# LPC11Exx register map
File version: 5
CPU: CM0 r0p0, little endian, no MPU, no FPU, 0x2 interrupt priority bits, 0x0 interrupts
Registers are 32-bit, read-write, reset 0x0 unless marked. A register's access mark holds for its fields unless they carry their own. Offsets are from the block's base; [hi:lo] are bit positions; {n}, {i} and the like mark numbered series.

## SYSCON — System control block
Base 0x40048000
0x00 SYSMEMREMAP — System memory remap
  [1:0] MAP — System memory remap. Value 0x3 is reserved.
    0=BOOT_LOADER_MODE_IN (Boot Loader Mode. Interrupt vectors are re-mapped to Boot ROM.); 1=USER_RAM_MODE_INTER (User RAM Mode. Interrupt vectors are re-mapped to Static RAM.); 2=USER_FLASH_MODE_INT (User Flash Mode. Interrupt vectors are not re-mapped and reside in Flash.)
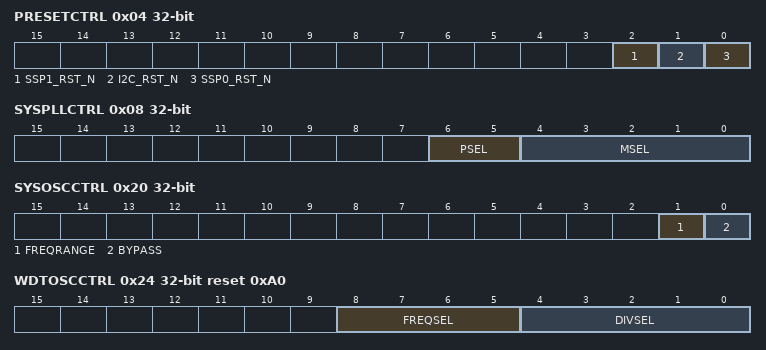
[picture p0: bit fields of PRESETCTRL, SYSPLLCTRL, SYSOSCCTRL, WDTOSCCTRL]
0x04 PRESETCTRL — Peripheral reset control
  [2] SSP1_RST_N — SSP1 reset control
    0=RESETS_THE_SSP1_PERI (Resets the SSP1 peripheral.); 1=SSP1_RESET_DE_ASSERT (SSP1 reset de-asserted.)
  [1] I2C_RST_N — I2C reset control
    0=RESETS_THE_I2C_PERIP (Resets the I2C peripheral.); 1=I2C_RESET_DE_ASSERTE (I2C reset de-asserted.)
  [0] SSP0_RST_N — SSP0 reset control
    0=RESETS_THE_SSP0_PERI (Resets the SSP0 peripheral.); 1=SSP0_RESET_DE_ASSERT (SSP0 reset de-asserted.)
0x08 SYSPLLCTRL — System PLL control
  [6:5] PSEL — Post divider ratio P. The division ratio is 2 x P.
    0=P_EQ_1 (P = 1); 1=P_EQ_2 (P = 2); 2=P_EQ_4 (P = 4); 3=P_EQ_8 (P = 8)
  [4:0] MSEL — Feedback divider value. The division value M is the programmed MSEL value + 1. 00000: Division ratio M = 1 to 11111: Division ratio M = 32
0x0C SYSPLLSTAT ro — System PLL status
  [0] LOCK — PLL lock status
    0=PLL_NOT_LOCKED; 1=PLL_LOCKED
0x20 SYSOSCCTRL — System oscillator control
  [1] FREQRANGE — Determines frequency range for Low-power oscillator.
    0=1__20_MHZ_FREQUENCY (1 - 20 MHz frequency range.); 1=15__25_MHZ_FREQUENC (15 - 25 MHz frequency range)
  [0] BYPASS — Bypass system oscillator
    0=OSCILLATOR_IS_NOT_BY (Oscillator is not bypassed.); 1=BYPASS_ENABLED_PLL_ (Bypass enabled. PLL input (sys_osc_clk) is fed directly from the XTALIN pin bypassing the oscillator. Use this mode when using an external clock source instead of the crystal oscillator.)
0x24 WDTOSCCTRL reset 0xA0 — Watchdog oscillator control
  [8:5] FREQSEL — Select watchdog oscillator analog output frequency (Fclkana).
    1=0_6_MHZ; 2=1_05_MHZ; 3=1_4_MHZ; 4=1_75_MHZ; 5=2_1_MHZ; 6=2_4_MHZ; 7=2_7_MHZ; 8=3_0_MHZ; 9=3_25_MHZ; 10=3_5_MHZ; 11=3_75_MHZ; 12=4_0_MHZ; 13=4_2_MHZ; 14=4_4_MHZ; 15=4_6_MHZ
  [4:0] DIVSEL — Select divider for Fclkana. wdt_osc_clk = Fclkana/ (2 x (1 + DIVSEL)) 00000: 2 x (1 + DIVSEL) = 2 00001: 2 x (1 + DIVSEL) = 4 to 11111: 2 x (1 + DIVSEL) = 64
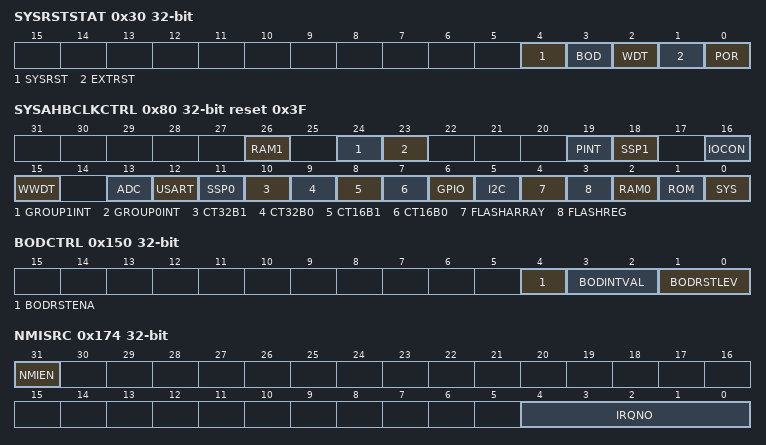
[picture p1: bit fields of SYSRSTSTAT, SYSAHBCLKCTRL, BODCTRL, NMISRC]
0x30 SYSRSTSTAT — System reset status register
  [4] SYSRST — Status of the software system reset
    0=NO_SYSTEM_RESET_DETE (No System reset detected); 1=SYSTEM_RESET_DETECTE (System reset detected. Writing a one clears this reset.)
  [3] BOD — Status of the Brown-out detect reset
    0=NO_BOD_RESET_DETECTE (No BOD reset detected); 1=BOD_RESET_DETECTED_ (BOD reset detected. Writing a one clears this reset.)
  [2] WDT — Status of the Watchdog reset
    0=NO_WDT_RESET_DETECTE (No WDT reset detected); 1=WDT_RESET_DETECTED_ (WDT reset detected. Writing a one clears this reset.)
  [1] EXTRST — External reset status
    0=NO_RESET_EVENT_DETEC (No reset event detected.); 1=RESET_DETECTED_WRIT (Reset detected. Writing a one clears this reset.)
  [0] POR — POR reset status
    0=NO_POR_DETECTED; 1=POR_DETECTED_WRITIN (POR detected. Writing a one clears this reset.)
0x40 SYSPLLCLKSEL — System PLL clock source select
  [1:0] SEL — System PLL clock source
    0=IRC; 1=CRYSTAL_OSCILLATOR_ (Crystal Oscillator (SYSOSC))
0x44 SYSPLLCLKUEN — System PLL clock source update enable
  [0] ENA — Enable system PLL clock source update
    0=NO_CHANGE; 1=UPDATE_CLOCK_SOURCE
0x70 MAINCLKSEL — Main clock source select
  [1:0] SEL — Clock source for main clock
    0=IRC_OSCILLATOR; 1=PLL_INPUT; 2=WATCHDOG_OSCILLATOR; 3=PLL_OUTPUT
0x74 MAINCLKUEN — Main clock source update enable
  [0] ENA — Enable main clock source update
    0=NO_CHANGE; 1=UPDATE_CLOCK_SOURCE
0x78 SYSAHBCLKDIV reset 0x1 — System clock divider
  [7:0] DIV — System AHB clock divider values 0: System clock disabled. 1: Divide by 1. to 255: Divide by 255.
0x80 SYSAHBCLKCTRL reset 0x3F — System clock control
  [26] RAM1 — Enables clock for the SRAM block at address range 0x2000 0000 to 0x2000 0800.
    0=DISABLE; 1=ENABLE
  [24] GROUP1INT — Enables clock to GPIO GROUP1 interrupt register interface.
    0=DISABLE; 1=ENABLE
  [23] GROUP0INT — Enables clock to GPIO GROUP0 interrupt register interface.
    0=DISABLE; 1=ENABLE
  [19] PINT — Enables clock to GPIO Pin interrupts register interface.
    0=DISABLE; 1=ENABLE
  [18] SSP1 — Enables clock for SSP1.
    0=DISABLE; 1=ENABLE
  [16] IOCON — Enables clock for I/O configuration block.
    0=DISABLE; 1=ENABLE
  [15] WWDT — Enables clock for WWDT.
    0=DISABLE; 1=ENABLE
  [13] ADC — Enables clock for ADC.
    0=DISABLE; 1=ENABLE
  [12] USART — Enables clock for UART.
    0=DISABLE; 1=ENABLE
  [11] SSP0 — Enables clock for SSP0.
    0=DISABLE; 1=ENABLE
  [10] CT32B1 — Enables clock for 32-bit counter/timer 1.
    0=DISABLE; 1=ENABLE
  [9] CT32B0 — Enables clock for 32-bit counter/timer 0.
    0=DISABLE; 1=ENABLE
  [8] CT16B1 — Enables clock for 16-bit counter/timer 1.
    0=DISABLE; 1=ENABLE
  [7] CT16B0 — Enables clock for 16-bit counter/timer 0.
    0=DISABLE; 1=ENABLE
  [6] GPIO — Enables clock for GPIO port registers.
    0=DISABLE; 1=ENABLE
  [5] I2C — Enables clock for I2C.
    0=DISABLE; 1=ENABLE
  [4] FLASHARRAY — Enables clock for flash array access.
    0=DISABLE; 1=ENABLE
  [3] FLASHREG — Enables clock for flash register interface.
    0=DISABLE; 1=ENABLE
  [2] RAM0 — Enables clock for the SRAM block at address range 0x1000 0000 to 0x1000 2000.
    0=DISABLE; 1=ENABLE
  [1] ROM — Enables clock for ROM.
    0=DISABLE; 1=ENABLE
  [0] SYS — Enables the clock for the AHB, the APB bridge, the Cortex-M0 FCLK and HCLK, SysCon, and the PMU. This bit is read only and always reads as 1.
    1=ENABLE
0x94 SSP0CLKDIV — SSP0 clock divider
  [7:0] DIV — SPI0_PCLK clock divider values. 0: System clock disabled. 1: Divide by 1. to 255: Divide by 255.
0x98 UARTCLKDIV — UART clock divider
  [7:0] DIV — UART_PCLK clock divider values 0: Disable UART_PCLK. 1: Divide by 1. to 255: Divide by 255.
0x9C SSP1CLKDIV — SSP1 clock divider
  [7:0] DIV — SSP1_PCLK clock divider values 0: Disable SSP1_PCLK. 1: Divide by 1. to 255: Divide by 255.
0xE0 CLKOUTSEL — CLKOUT clock source select
  [1:0] SEL — CLKOUT clock source
    0=IRC_OSCILLATOR; 1=CRYSTAL_OSCILLATOR_ (Crystal oscillator (SYSOSC)); 2=LF_OSCILLATOR; 3=MAIN_CLOCK
0xE4 CLKOUTUEN — CLKOUT clock source update enable
  [0] ENA — Enable CLKOUT clock source update
    0=NO_CHANGE; 1=UPDATE_CLOCK_SOURCE
0xE8 CLKOUTDIV — CLKOUT clock divider
  [7:0] DIV — CLKOUT clock divider values 0: Disable CLKOUT clock divider. 1: Divide by 1. to 255: Divide by 255.
0x100 PIOPORCAP0 ro reset not defined — POR captured PIO status 0
  [23:0] PIOSTAT — State of PIO0_23 through PIO0_0 at power-on reset
0x104 PIOPORCAP1 ro reset not defined — POR captured PIO status 1
  [31:0] PIOSTAT — State of PIO1_31 through PIO1_0 at power-on reset
0x150 BODCTRL — Brown-Out Detect
  [4] BODRSTENA — BOD reset enable
    0=DISABLE_RESET_FUNCTI (Disable reset function.); 1=ENABLE_RESET_FUNCTIO (Enable reset function.)
  [3:2] BODINTVAL — BOD interrupt level
    0=LEVEL_0_RESERVED_; 1=LEVEL_1THE_INTERRUP (Level 1:The interrupt assertion threshold voltage is 2.22 V; the interrupt de-assertion threshold voltage is 2.35 V.); 2=LEVEL_2_THE_INTERRU (Level 2: The interrupt assertion threshold voltage is 2.52 V; the interrupt de-assertion threshold voltage is 2.66 V.); 3=LEVEL_3_THE_INTERRU (Level 3: The interrupt assertion threshold voltage is 2.80 V; the interrupt de-assertion threshold voltage is 2.90 V.)
  [1:0] BODRSTLEV — BOD reset level
    0=LEVEL_0_THE_RESET_A (Level 0: The reset assertion threshold voltage is 1.46 V; the reset de-assertion threshold voltage is 1.63 V.); 1=LEVEL_1_THE_RESET_A (Level 1: The reset assertion threshold voltage is 2.06 V; the reset de-assertion threshold voltage is 2.15 V.); 2=LEVEL_2_THE_RESET_A (Level 2: The reset assertion threshold voltage is 2.35 V; the reset de-assertion threshold voltage is 2.43 V.); 3=LEVEL_3_THE_RESET_A (Level 3: The reset assertion threshold voltage is 2.63 V; the reset de-assertion threshold voltage is 2.71 V.)
0x154 SYSTCKCAL — System tick counter calibration
  [25:0] CAL — System tick timer calibration value
0x170 IRQLATENCY reset 0x10 — IQR delay. Allows trade-off between interrupt latency and determinism.
  [7:0] LATENCY — 8-bit latency value
0x174 NMISRC — NMI Source Control
  [31] NMIEN — Write a 1 to this bit to enable the Non-Maskable Interrupt (NMI) source selected by bits 4:0.
  [4:0] IRQNO — The IRQ number of the interrupt that acts as the Non-Maskable Interrupt (NMI) if bit 31 is 1. See Table 49 for the list of interrupt sources and their IRQ numbers.
{0x178+4i} PINTSEL{i} (i=0..7) — GPIO Pin Interrupt Select register 0
  [5:0] INTPIN — Pin number select for pin interrupt. (P0_0 to P0_23 correspond to numbers 0 to 23 and PIO1_0 to PIO1_31 correspond to numbers 24 to 55).
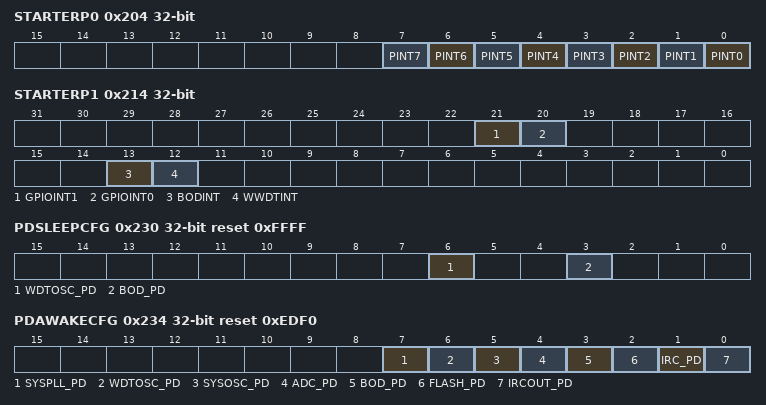
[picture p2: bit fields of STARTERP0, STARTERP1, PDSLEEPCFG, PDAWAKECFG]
0x204 STARTERP0 — Start logic 0 interrupt wake-up enable register 0
  [all] fields
    0=DISABLED; 1=ENABLED
  [n] PINT{n} (n=0..7) — Pin interrupt {n} wake-up
0x214 STARTERP1 — Start logic 1 interrupt wake-up enable register 1
  [all] fields
    0=DISABLED; 1=ENABLED
  [21] GPIOINT1 — GPIO GROUP1 interrupt wake-up
  [20] GPIOINT0 — GPIO GROUP0 interrupt wake-up
  [13] BODINT — Brown Out Detect (BOD) interrupt wake-up
  [12] WWDTINT — WWDT interrupt wake-up
0x230 PDSLEEPCFG reset 0xFFFF — Power-down states in deep-sleep mode
  [6] WDTOSC_PD — Watchdog oscillator power-down control for Deep-sleep and Power-down mode
    0=POWERED; 1=POWERED_DOWN
  [3] BOD_PD — BOD power-down control for Deep-sleep and Power-down mode
    0=POWERED; 1=POWERED_DOWN
0x234 PDAWAKECFG reset 0xEDF0 — Power-down states for wake-up from deep-sleep
  [all] fields
    0=POWERED; 1=POWERED_DOWN
  [7] SYSPLL_PD — System PLL wake-up configuration
  [6] WDTOSC_PD — Watchdog oscillator wake-up configuration
  [5] SYSOSC_PD — Crystal oscillator wake-up configuration
  [4] ADC_PD — ADC wake-up configuration
  [3] BOD_PD — BOD wake-up configuration
  [2] FLASH_PD — Flash wake-up configuration
  [1] IRC_PD — IRC oscillator power-down wake-up configuration
  [0] IRCOUT_PD — IRC oscillator output wake-up configuration
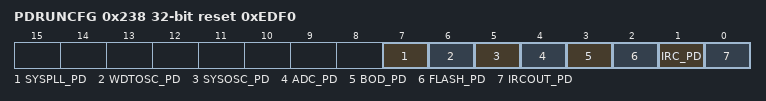
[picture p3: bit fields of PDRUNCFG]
0x238 PDRUNCFG reset 0xEDF0 — Power configuration register
  [all] fields
    0=POWERED; 1=POWERED_DOWN
  [7] SYSPLL_PD — System PLL power-down
  [6] WDTOSC_PD — Watchdog oscillator power-down
  [5] SYSOSC_PD — Crystal oscillator power-down
  [4] ADC_PD — ADC power-down
  [3] BOD_PD — BOD power-down
  [2] FLASH_PD — Flash power-down
  [1] IRC_PD — IRC oscillator power-down
  [0] IRCOUT_PD — IRC oscillator output power-down
0x3F4 DEVICE_ID ro reset not defined
  [31:0] DEVICEID — Device ID numbers for LPC11Exx parts LPC11E11FHN33/101 = 0x293E 902B LPC11E12FBD48/201 = 0x2954 502B LPC11E13FBD48/301 = 0x296A 102B LPC11E14FHN33/401 = 0x2980 102B LPC11E14FBD48/401 = 0x2980 102B LPC11E14FBD64/401 = 0x2980 102B
